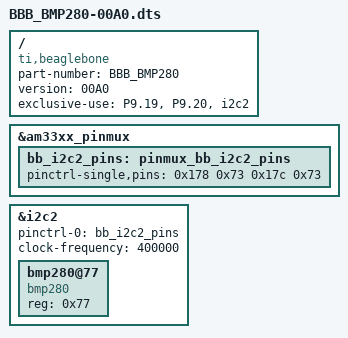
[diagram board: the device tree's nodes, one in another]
/*
 * Custom overlay for BMP280 for Beaglebone Blue
 * Author: Kiran Kumar Lekkala
 */
/dts-v1/;
/plugin/;

/ {
	compatible = "ti,beaglebone", "ti,beaglebone-black", "ti,beaglebone-green";

	/* identification */
	part-number = "BBB_BMP280";
	version = "00A0";

	/* state the resources this cape uses */
	exclusive-use =
		/* the pin header uses */
		"P9.19",	/* i2c2_sda */
		"P9.20",	/* i2c2_scl */
		/* the hardware ip uses */
		"i2c2";

	fragment@0 {
		target = <&am33xx_pinmux>;
		__overlay__ {
			bb_i2c2_pins: pinmux_bb_i2c2_pins {
				pinctrl-single,pins = <
					0x178 0x73	/* i2c2_sda, SLEWCTRL_SLOW | INPUT_PULLUP | MODE3 */
					0x17c 0x73	/* i2c2_scl, SLEWCTRL_SLOW | INPUT_PULLUP | MODE3 */
				>;
			};
		};
	};

	fragment@1 {
		target = <&i2c2>;
		__overlay__ {
			status = "okay";
			pinctrl-names = "default";
			pinctrl-0 = <&bb_i2c2_pins>;

			/* this is the configuration part */
			clock-frequency = <400000>;

			#address-cells = <1>;
			#size-cells = <0>;

			/* add any i2c devices on the bus here */

			bmp280@77 {
				compatible = "bmp280";
				reg = <0x77>;
	};
		};
	};
};
